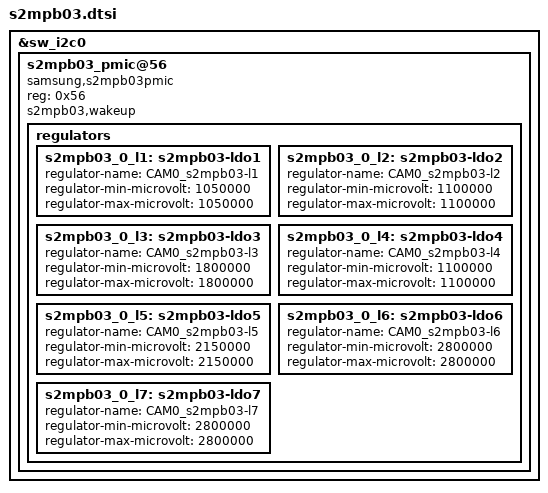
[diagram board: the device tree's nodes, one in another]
&sw_i2c0 {
	#address-cells = <1>;
	#size-cells = <0>;
	status = "okay";
	s2mpb03_pmic@56 {
		compatible = "samsung,s2mpb03pmic";
		reg = <0x56>;
		s2mpb03,wakeup;

		regulators {
			s2mpb03_0_l1: s2mpb03-ldo1 {
				regulator-name = "CAM0_s2mpb03-l1";
				regulator-min-microvolt = <1050000>;
				regulator-max-microvolt = <1050000>;
				 
				 
			};

			s2mpb03_0_l2: s2mpb03-ldo2 {
				regulator-name = "CAM0_s2mpb03-l2";
				regulator-min-microvolt = <1100000>;
				regulator-max-microvolt = <1100000>;
				 
				 
			};

			s2mpb03_0_l3: s2mpb03-ldo3 {
				regulator-name = "CAM0_s2mpb03-l3";
				regulator-min-microvolt = <1800000>;
				regulator-max-microvolt = <1800000>;
				 
				 
			};

			s2mpb03_0_l4: s2mpb03-ldo4 {
				regulator-name = "CAM0_s2mpb03-l4";
				regulator-min-microvolt = <1100000>;
				regulator-max-microvolt = <1100000>;
				 
				 
			};

			s2mpb03_0_l5: s2mpb03-ldo5 {
				regulator-name = "CAM0_s2mpb03-l5";
				regulator-min-microvolt = <2150000>;
				regulator-max-microvolt = <2150000>;
				 
				 
			};

			s2mpb03_0_l6: s2mpb03-ldo6 {
				regulator-name = "CAM0_s2mpb03-l6";
				regulator-min-microvolt = <2800000>;
				regulator-max-microvolt = <2800000>;
				 
				 
			};

			s2mpb03_0_l7: s2mpb03-ldo7 {
				regulator-name = "CAM0_s2mpb03-l7";
				regulator-min-microvolt = <2800000>;
				regulator-max-microvolt = <2800000>;
				 
				 
			};
		};
	};
};
